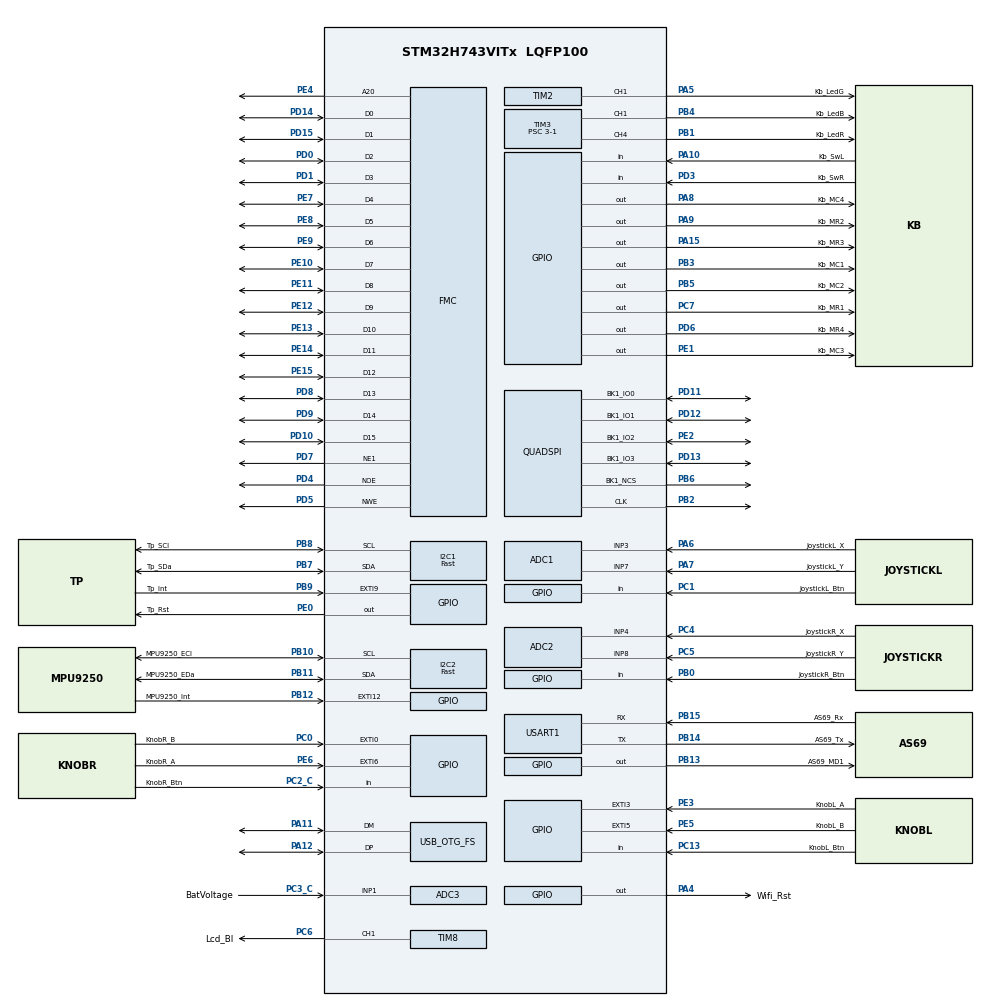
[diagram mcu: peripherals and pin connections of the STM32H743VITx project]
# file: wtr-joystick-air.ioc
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ADC1.Channel-0\#ChannelRegularConversion=ADC_CHANNEL_7
ADC1.Channel-1\#ChannelRegularConversion=ADC_CHANNEL_3
ADC1.ClockPrescaler=ADC_CLOCK_ASYNC_DIV8
ADC1.ClockPrescalerADC3=ADC_CLOCK_ASYNC_DIV8
ADC1.ContinuousConvMode=ENABLE
ADC1.ConversionDataManagement=ADC_CONVERSIONDATA_DMA_CIRCULAR
ADC1.EOCSelection=ADC_EOC_SEQ_CONV
ADC1.NbrOfConversion=2
ADC1.NbrOfConversionFlag=1
ADC1.OffsetNumber-0\#ChannelRegularConversion=ADC_OFFSET_NONE
ADC1.OffsetNumber-1\#ChannelRegularConversion=ADC_OFFSET_NONE
ADC1.OffsetSignedSaturation-0\#ChannelRegularConversion=DISABLE
ADC1.OffsetSignedSaturation-1\#ChannelRegularConversion=DISABLE
ADC1.Overrun=ADC_OVR_DATA_OVERWRITTEN
ADC1.OversamplingMode=ENABLE
ADC1.Rank-0\#ChannelRegularConversion=1
ADC1.Rank-1\#ChannelRegularConversion=2
ADC1.Ratio=128
ADC1.RightBitShift=ADC_RIGHTBITSHIFT_7
ADC1.SamplingTime-0\#ChannelRegularConversion=ADC_SAMPLETIME_16CYCLES_5
ADC1.SamplingTime-1\#ChannelRegularConversion=ADC_SAMPLETIME_16CYCLES_5
ADC1.master=1
ADC2.Channel-0\#ChannelRegularConversion=ADC_CHANNEL_8
ADC2.Channel-1\#ChannelRegularConversion=ADC_CHANNEL_4
ADC2.ClockPrescaler=ADC_CLOCK_ASYNC_DIV8
ADC2.ContinuousConvMode=ENABLE
ADC2.ConversionDataManagement=ADC_CONVERSIONDATA_DMA_CIRCULAR
ADC2.EOCSelection=ADC_EOC_SEQ_CONV
ADC2.NbrOfConversion=2
ADC2.NbrOfConversionFlag=1
ADC2.OffsetNumber-0\#ChannelRegularConversion=ADC_OFFSET_NONE
ADC2.OffsetNumber-1\#ChannelRegularConversion=ADC_OFFSET_NONE
ADC2.OffsetSignedSaturation-0\#ChannelRegularConversion=DISABLE
ADC2.OffsetSignedSaturation-1\#ChannelRegularConversion=DISABLE
ADC2.Overrun=ADC_OVR_DATA_OVERWRITTEN
ADC2.OversamplingMode=ENABLE
ADC2.Rank-0\#ChannelRegularConversion=1
ADC2.Rank-1\#ChannelRegularConversion=2
ADC2.Ratio=128
ADC2.RightBitShift=ADC_RIGHTBITSHIFT_7
ADC2.SamplingTime-0\#ChannelRegularConversion=ADC_SAMPLETIME_16CYCLES_5
ADC2.SamplingTime-1\#ChannelRegularConversion=ADC_SAMPLETIME_16CYCLES_5
ADC3.Channel-0\#ChannelRegularConversion=ADC_CHANNEL_1
ADC3.Channel-1\#ChannelRegularConversion=ADC_CHANNEL_VBAT
ADC3.Channel-2\#ChannelRegularConversion=ADC_CHANNEL_TEMPSENSOR
ADC3.Channel-3\#ChannelRegularConversion=ADC_CHANNEL_VREFINT
ADC3.ClockPrescaler=ADC_CLOCK_ASYNC_DIV8
ADC3.ClockPrescalerADC3=ADC_CLOCK_ASYNC_DIV8
ADC3.ContinuousConvMode=ENABLE
ADC3.ConversionDataManagement=ADC_CONVERSIONDATA_DMA_CIRCULAR
ADC3.EOCSelection=ADC_EOC_SEQ_CONV
ADC3.NbrOfConversion=4
ADC3.NbrOfConversionFlag=1
ADC3.OffsetNumber-0\#ChannelRegularConversion=ADC_OFFSET_NONE
ADC3.OffsetNumber-1\#ChannelRegularConversion=ADC_OFFSET_NONE
ADC3.OffsetNumber-2\#ChannelRegularConversion=ADC_OFFSET_NONE
ADC3.OffsetNumber-3\#ChannelRegularConversion=ADC_OFFSET_NONE
ADC3.OffsetSignedSaturation-0\#ChannelRegularConversion=DISABLE
ADC3.OffsetSignedSaturation-1\#ChannelRegularConversion=DISABLE
ADC3.OffsetSignedSaturation-2\#ChannelRegularConversion=DISABLE
ADC3.OffsetSignedSaturation-3\#ChannelRegularConversion=DISABLE
ADC3.Overrun=ADC_OVR_DATA_OVERWRITTEN
ADC3.OversamplingMode=ENABLE
ADC3.Rank-0\#ChannelRegularConversion=1
ADC3.Rank-1\#ChannelRegularConversion=2
ADC3.Rank-2\#ChannelRegularConversion=3
ADC3.Rank-3\#ChannelRegularConversion=4
ADC3.Ratio=1024
ADC3.RightBitShift=ADC_RIGHTBITSHIFT_10
ADC3.SamplingTime-0\#ChannelRegularConversion=ADC_SAMPLETIME_810CYCLES_5
ADC3.SamplingTime-1\#ChannelRegularConversion=ADC_SAMPLETIME_810CYCLES_5
ADC3.SamplingTime-2\#ChannelRegularConversion=ADC_SAMPLETIME_810CYCLES_5
ADC3.SamplingTime-3\#ChannelRegularConversion=ADC_SAMPLETIME_810CYCLES_5
CORTEX_M7.AccessPermission_S-Cortex_Memory_Protection_Unit_Region2_Settings_S=MPU_REGION_FULL_ACCESS
CORTEX_M7.AccessPermission_S-Cortex_Memory_Protection_Unit_Region3_Settings_S=MPU_REGION_FULL_ACCESS
CORTEX_M7.AccessPermission_S-Cortex_Memory_Protection_Unit_Region4_Settings_S=MPU_REGION_FULL_ACCESS
CORTEX_M7.AccessPermission_S-Cortex_Memory_Protection_Unit_Region5_Settings_S=MPU_REGION_FULL_ACCESS
CORTEX_M7.BaseAddress_S-Cortex_Memory_Protection_Unit_Region2_Settings_S=0x24000000
CORTEX_M7.BaseAddress_S-Cortex_Memory_Protection_Unit_Region3_Settings_S=0x30000000
CORTEX_M7.BaseAddress_S-Cortex_Memory_Protection_Unit_Region4_Settings_S=0x38000000
CORTEX_M7.BaseAddress_S-Cortex_Memory_Protection_Unit_Region5_Settings_S=0x60000000
CORTEX_M7.CPU_DCache=Enabled
CORTEX_M7.CPU_ICache=Enabled
CORTEX_M7.DisableExec_S-Cortex_Memory_Protection_Unit_Region5_Settings_S=MPU_INSTRUCTION_ACCESS_DISABLE
CORTEX_M7.Enable_S-Cortex_Memory_Protection_Unit_Region1_Settings_S=__NULL
CORTEX_M7.Enable_S-Cortex_Memory_Protection_Unit_Region2_Settings_S=MPU_REGION_ENABLE
CORTEX_M7.Enable_S-Cortex_Memory_Protection_Unit_Region3_Settings_S=MPU_REGION_ENABLE
CORTEX_M7.Enable_S-Cortex_Memory_Protection_Unit_Region4_Settings_S=MPU_REGION_ENABLE
CORTEX_M7.Enable_S-Cortex_Memory_Protection_Unit_Region5_Settings_S=MPU_REGION_ENABLE
CORTEX_M7.IsCacheable_S-Cortex_Memory_Protection_Unit_Region2_Settings_S=MPU_ACCESS_CACHEABLE
CORTEX_M7.IsCacheable_S-Cortex_Memory_Protection_Unit_Region3_Settings_S=MPU_ACCESS_CACHEABLE
CORTEX_M7.IsCacheable_S-Cortex_Memory_Protection_Unit_Region4_Settings_S=MPU_ACCESS_CACHEABLE
CORTEX_M7.IsShareable_S-Cortex_Memory_Protection_Unit_Region3_Settings_S=MPU_ACCESS_SHAREABLE
CORTEX_M7.IsShareable_S-Cortex_Memory_Protection_Unit_Region4_Settings_S=MPU_ACCESS_SHAREABLE
CORTEX_M7.IsShareable_S-Cortex_Memory_Protection_Unit_Region5_Settings_S=MPU_ACCESS_SHAREABLE
CORTEX_M7.Size_S-Cortex_Memory_Protection_Unit_Region2_Settings_S=MPU_REGION_SIZE_512KB
CORTEX_M7.Size_S-Cortex_Memory_Protection_Unit_Region3_Settings_S=MPU_REGION_SIZE_512KB
CORTEX_M7.Size_S-Cortex_Memory_Protection_Unit_Region4_Settings_S=MPU_REGION_SIZE_64KB
CORTEX_M7.Size_S-Cortex_Memory_Protection_Unit_Region5_Settings_S=MPU_REGION_SIZE_1GB
CORTEX_M7.default_mode_Activation=1
Dma.ADC1.1.Direction=DMA_PERIPH_TO_MEMORY
Dma.ADC1.1.EventEnable=DISABLE
Dma.ADC1.1.FIFOMode=DMA_FIFOMODE_ENABLE
Dma.ADC1.1.FIFOThreshold=DMA_FIFO_THRESHOLD_1QUARTERFULL
Dma.ADC1.1.Instance=DMA1_Stream1
Dma.ADC1.1.MemBurst=DMA_MBURST_SINGLE
Dma.ADC1.1.MemDataAlignment=DMA_MDATAALIGN_HALFWORD
Dma.ADC1.1.MemInc=DMA_MINC_ENABLE
Dma.ADC1.1.Mode=DMA_CIRCULAR
Dma.ADC1.1.PeriphBurst=DMA_PBURST_SINGLE
Dma.ADC1.1.PeriphDataAlignment=DMA_PDATAALIGN_HALFWORD
Dma.ADC1.1.PeriphInc=DMA_PINC_DISABLE
Dma.ADC1.1.Polarity=HAL_DMAMUX_REQ_GEN_RISING
Dma.ADC1.1.Priority=DMA_PRIORITY_LOW
Dma.ADC1.1.RequestNumber=1
Dma.ADC1.1.SignalID=NONE
Dma.ADC1.1.SyncEnable=DISABLE
Dma.ADC1.1.SyncPolarity=HAL_DMAMUX_SYNC_NO_EVENT
Dma.ADC1.1.SyncRequestNumber=1
Dma.ADC1.1.SyncSignalID=NONE
Dma.ADC2.2.Direction=DMA_PERIPH_TO_MEMORY
Dma.ADC2.2.EventEnable=DISABLE
Dma.ADC2.2.FIFOMode=DMA_FIFOMODE_ENABLE
Dma.ADC2.2.FIFOThreshold=DMA_FIFO_THRESHOLD_1QUARTERFULL
Dma.ADC2.2.Instance=DMA1_Stream2
Dma.ADC2.2.MemBurst=DMA_MBURST_SINGLE
Dma.ADC2.2.MemDataAlignment=DMA_MDATAALIGN_HALFWORD
Dma.ADC2.2.MemInc=DMA_MINC_ENABLE
Dma.ADC2.2.Mode=DMA_CIRCULAR
Dma.ADC2.2.PeriphBurst=DMA_PBURST_SINGLE
Dma.ADC2.2.PeriphDataAlignment=DMA_PDATAALIGN_HALFWORD
Dma.ADC2.2.PeriphInc=DMA_PINC_DISABLE
Dma.ADC2.2.Polarity=HAL_DMAMUX_REQ_GEN_RISING
Dma.ADC2.2.Priority=DMA_PRIORITY_LOW
Dma.ADC2.2.RequestNumber=1
Dma.ADC2.2.SignalID=NONE
Dma.ADC2.2.SyncEnable=DISABLE
Dma.ADC2.2.SyncPolarity=HAL_DMAMUX_SYNC_NO_EVENT
Dma.ADC2.2.SyncRequestNumber=1
Dma.ADC2.2.SyncSignalID=NONE
Dma.ADC3.0.Direction=DMA_PERIPH_TO_MEMORY
Dma.ADC3.0.EventEnable=DISABLE
Dma.ADC3.0.FIFOMode=DMA_FIFOMODE_ENABLE
Dma.ADC3.0.FIFOThreshold=DMA_FIFO_THRESHOLD_HALFFULL
Dma.ADC3.0.Instance=DMA1_Stream0
Dma.ADC3.0.MemBurst=DMA_MBURST_INC4
Dma.ADC3.0.MemDataAlignment=DMA_MDATAALIGN_HALFWORD
Dma.ADC3.0.MemInc=DMA_MINC_ENABLE
Dma.ADC3.0.Mode=DMA_CIRCULAR
Dma.ADC3.0.PeriphBurst=DMA_PBURST_SINGLE
Dma.ADC3.0.PeriphDataAlignment=DMA_PDATAALIGN_HALFWORD
Dma.ADC3.0.PeriphInc=DMA_PINC_DISABLE
Dma.ADC3.0.Polarity=HAL_DMAMUX_REQ_GEN_RISING
Dma.ADC3.0.Priority=DMA_PRIORITY_LOW
Dma.ADC3.0.RequestNumber=1
Dma.ADC3.0.SignalID=NONE
Dma.ADC3.0.SyncEnable=DISABLE
Dma.ADC3.0.SyncPolarity=HAL_DMAMUX_SYNC_NO_EVENT
Dma.ADC3.0.SyncRequestNumber=1
Dma.ADC3.0.SyncSignalID=NONE
Dma.Request0=ADC3
Dma.Request1=ADC1
Dma.Request2=ADC2
Dma.Request3=USART1_TX
Dma.USART1_TX.3.Direction=DMA_MEMORY_TO_PERIPH
Dma.USART1_TX.3.EventEnable=DISABLE
Dma.USART1_TX.3.FIFOMode=DMA_FIFOMODE_DISABLE
Dma.USART1_TX.3.Instance=DMA2_Stream0
Dma.USART1_TX.3.MemDataAlignment=DMA_MDATAALIGN_BYTE
Dma.USART1_TX.3.MemInc=DMA_MINC_ENABLE
Dma.USART1_TX.3.Mode=DMA_NORMAL
Dma.USART1_TX.3.PeriphDataAlignment=DMA_PDATAALIGN_BYTE
Dma.USART1_TX.3.PeriphInc=DMA_PINC_DISABLE
Dma.USART1_TX.3.Polarity=HAL_DMAMUX_REQ_GEN_RISING
Dma.USART1_TX.3.Priority=DMA_PRIORITY_HIGH
Dma.USART1_TX.3.RequestNumber=1
Dma.USART1_TX.3.SignalID=NONE
Dma.USART1_TX.3.SyncEnable=DISABLE
Dma.USART1_TX.3.SyncPolarity=HAL_DMAMUX_SYNC_NO_EVENT
Dma.USART1_TX.3.SyncRequestNumber=1
Dma.USART1_TX.3.SyncSignalID=NONE
FMC.AddressSetupTime1=0
FMC.BusTurnAroundDuration1=0
FMC.DataSetupTime1=110
FMC.ExtendedAddressSetupTime1=0
FMC.ExtendedBusTurnAroundDuration1=0
FMC.ExtendedDataSetupTime1=5
FMC.ExtendedMode1=FMC_EXTENDED_MODE_ENABLE
FREERTOS.INCLUDE_vTaskDelayUntil=1
FREERTOS.Tasks01=defaultTask,0,512,StartDefaultTask,As weak,NULL,Dynamic,NULL,NULL
FREERTOS.configENABLE_FPU=1
FREERTOS.configGENERATE_RUN_TIME_STATS=1
FREERTOS.configMAX_TASK_NAME_LEN=32
FREERTOS.configRECORD_STACK_HIGH_ADDRESS=1
FREERTOS.configTOTAL_HEAP_SIZE=131072
FREERTOS.configUSE_COUNTING_SEMAPHORES=1
FREERTOS.configUSE_NEWLIB_REENTRANT=1
FREERTOS.configUSE_POSIX_ERRNO=1
FREERTOS.configUSE_RECURSIVE_MUTEXES=1
FREERTOS.configUSE_STATS_FORMATTING_FUNCTIONS=0
FREERTOS.configUSE_TICKLESS_IDLE=2
FREERTOS.configUSE_TICK_HOOK=0
FREERTOS.configUSE_TRACE_FACILITY=0
I2C1.I2C_Speed_Mode=I2C_Fast
I2C1.Timing=0x00B03FDB
I2C2.I2C_Speed_Mode=I2C_Fast
I2C2.Timing=0x00B03FDB
Mcu.Family=STM32H7
Mcu.Name=STM32H743VITx
Mcu.Package=LQFP100
Mdma.MDMA_Channel0.Request0=SW
Mdma.MDMA_Channel0.RequestsNb=1
Mdma.MDMA_Channel0.SW.0.BlockCount=0
Mdma.MDMA_Channel0.SW.0.BlockDataLength=0
Mdma.MDMA_Channel0.SW.0.BufferTransferLength=2
Mdma.MDMA_Channel0.SW.0.CircularMode=MDMA_LINEAR_LIST
Mdma.MDMA_Channel0.SW.0.DataAlignment=MDMA_DATAALIGN_PACKENABLE
Mdma.MDMA_Channel0.SW.0.DestBlockAddressOffset=0
Mdma.MDMA_Channel0.SW.0.DestBurst=MDMA_DEST_BURST_2BEATS
Mdma.MDMA_Channel0.SW.0.DestDataSize=MDMA_DEST_DATASIZE_HALFWORD
Mdma.MDMA_Channel0.SW.0.DestinationInc=MDMA_DEST_INC_DISABLE
Mdma.MDMA_Channel0.SW.0.DstAddress=0
Mdma.MDMA_Channel0.SW.0.Endianness=MDMA_LITTLE_ENDIANNESS_PRESERVE
Mdma.MDMA_Channel0.SW.0.Instance=MDMA_Channel0
Mdma.MDMA_Channel0.SW.0.MaskAddress=0
Mdma.MDMA_Channel0.SW.0.MaskData=0
Mdma.MDMA_Channel0.SW.0.Priority=MDMA_PRIORITY_LOW
Mdma.MDMA_Channel0.SW.0.Rank=First
Mdma.MDMA_Channel0.SW.0.SourceBlockAddressOffset=0
Mdma.MDMA_Channel0.SW.0.SourceBurst=MDMA_SOURCE_BURST_2BEATS
Mdma.MDMA_Channel0.SW.0.SourceDataSize=MDMA_SRC_DATASIZE_HALFWORD
Mdma.MDMA_Channel0.SW.0.SourceInc=MDMA_SRC_INC_HALFWORD
Mdma.MDMA_Channel0.SW.0.SrcAddress=0
Mdma.MDMA_Channel0.SW.0.TransferTriggerMode=MDMA_REPEAT_BLOCK_TRANSFER
Mdma.RequestSet0=MDMA_Channel0
Mdma.RequestSetsNb=1
NVIC.EXTI0_IRQn=true\:5\:0\:true\:false\:true\:true\:true\:true\:true
NVIC.EXTI3_IRQn=true\:5\:0\:true\:false\:true\:true\:true\:true\:true
NVIC.EXTI9_5_IRQn=true\:5\:0\:true\:false\:true\:true\:true\:true\:true
NVIC.MDMA_IRQn=true\:8\:0\:true\:false\:true\:true\:false\:true\:true
NVIC.OTG_FS_IRQn=true\:11\:0\:true\:false\:true\:true\:true\:true\:true
NVIC.PriorityGroup=NVIC_PRIORITYGROUP_4
NVIC.TIM7_IRQn=true\:1\:0\:true\:false\:true\:false\:false\:true\:true
NVIC.TimeBase=TIM7_IRQn
NVIC.TimeBaseIP=TIM7
NVIC.USART1_IRQn=true\:5\:0\:false\:false\:true\:true\:true\:true\:true
PA0.GPIO_Label=Kb_UartTx
PA0.Signal=UART4_TX
PA1.GPIO_Label=Kb_UartRx
PA1.Signal=UART4_RX
PA10.GPIO_Label=Kb_SwL
PA10.GPIO_PuPd=GPIO_PULLDOWN
PA10.Signal=GPIO_Input
PA11.GPIO_Speed=GPIO_SPEED_FREQ_HIGH
PA11.Mode=Device_Only
PA11.Signal=USB_OTG_FS_DM
PA12.GPIO_Speed=GPIO_SPEED_FREQ_HIGH
PA12.Mode=Device_Only
PA12.Signal=USB_OTG_FS_DP
PA13\ (JTMS/SWDIO).Mode=Serial_Wire
PA13\ (JTMS/SWDIO).Signal=DEBUG_JTMS-SWDIO
PA14\ (JTCK/SWCLK).Mode=Serial_Wire
PA14\ (JTCK/SWCLK).Signal=DEBUG_JTCK-SWCLK
PA15\ (JTDI).GPIO_Label=Kb_MR3
PA15\ (JTDI).GPIO_ModeDefaultOutputPP=GPIO_MODE_OUTPUT_OD
PA15\ (JTDI).GPIO_PuPd=GPIO_PULLUP
PA15\ (JTDI).PinState=GPIO_PIN_SET
PA15\ (JTDI).Signal=GPIO_Output
PA2.GPIO_Label=Wifi_Tx
PA2.GPIO_Speed=GPIO_SPEED_FREQ_MEDIUM
PA2.Signal=USART2_TX
PA3.GPIO_Label=Wifi_Rx
PA3.GPIO_Speed=GPIO_SPEED_FREQ_MEDIUM
PA3.Signal=USART2_RX
PA4.GPIO_Label=Wifi_Rst
PA4.Signal=GPIO_Output
PA5.GPIO_Label=Kb_LedG
PA5.Signal=S_TIM2_CH1_ETR
PA6.GPIO_Label=JoystickL_X
PA6.Signal=ADCx_INP3
PA7.GPIO_Label=JoystickL_Y
PA7.Signal=ADCx_INP7
PA8.GPIO_Label=Kb_MC4
PA8.GPIO_ModeDefaultOutputPP=GPIO_MODE_OUTPUT_OD
PA8.GPIO_PuPd=GPIO_PULLUP
PA8.PinState=GPIO_PIN_SET
PA8.Signal=GPIO_Output
PA9.GPIO_Label=Kb_MR2
PA9.GPIO_ModeDefaultOutputPP=GPIO_MODE_OUTPUT_OD
PA9.GPIO_PuPd=GPIO_PULLUP
PA9.PinState=GPIO_PIN_SET
PA9.Signal=GPIO_Output
PB0.GPIO_Label=JoystickR_Btn
PB0.GPIO_PuPd=GPIO_PULLUP
PB0.Signal=GPIO_Input
PB1.GPIO_Label=Kb_LedR
PB1.Signal=S_TIM3_CH4
PB10.GPIO_Label=MPU9250_ECl
PB10.GPIO_Speed=GPIO_SPEED_FREQ_MEDIUM
PB10.Mode=I2C
PB10.Signal=I2C2_SCL
PB11.GPIO_Label=MPU9250_EDa
PB11.GPIO_Speed=GPIO_SPEED_FREQ_MEDIUM
PB11.Mode=I2C
PB11.Signal=I2C2_SDA
PB12.GPIO_Label=MPU9250_Int
PB12.Signal=GPXTI12
PB13.GPIO_Label=AS69_MD1
PB13.PinState=GPIO_PIN_SET
PB13.Signal=GPIO_Output
PB14.GPIO_Label=AS69_Tx
PB14.Mode=Asynchronous
PB14.Signal=USART1_TX
PB15.GPIO_Label=AS69_Rx
PB15.Mode=Asynchronous
PB15.Signal=USART1_RX
PB2.GPIO_Speed=GPIO_SPEED_FREQ_HIGH
PB2.Mode=Single Bank 1
PB2.Signal=QUADSPI_CLK
PB3\ (JTDO/TRACESWO).GPIO_Label=Kb_MC1
PB3\ (JTDO/TRACESWO).GPIO_ModeDefaultOutputPP=GPIO_MODE_OUTPUT_OD
PB3\ (JTDO/TRACESWO).GPIO_PuPd=GPIO_PULLUP
PB3\ (JTDO/TRACESWO).PinState=GPIO_PIN_SET
PB3\ (JTDO/TRACESWO).Signal=GPIO_Output
PB4\ (NJTRST).GPIO_Label=Kb_LedB
PB4\ (NJTRST).Signal=S_TIM3_CH1
PB5.GPIO_Label=Kb_MC2
PB5.GPIO_ModeDefaultOutputPP=GPIO_MODE_OUTPUT_OD
PB5.GPIO_PuPd=GPIO_PULLUP
PB5.PinState=GPIO_PIN_SET
PB5.Signal=GPIO_Output
PB6.GPIO_Speed=GPIO_SPEED_FREQ_LOW
PB6.Mode=Single Bank 1
PB6.Signal=QUADSPI_BK1_NCS
PB7.GPIO_Label=Tp_SDa
PB7.GPIO_Speed=GPIO_SPEED_FREQ_MEDIUM
PB7.Mode=I2C
PB7.Signal=I2C1_SDA
PB8.GPIO_Label=Tp_SCl
PB8.GPIO_Speed=GPIO_SPEED_FREQ_MEDIUM
PB8.Mode=I2C
PB8.Signal=I2C1_SCL
PB9.GPIO_Label=Tp_Int
PB9.Signal=GPXTI9
PC0.GPIO_Label=KnobR_B
PC0.GPIO_ModeDefaultEXTI=GPIO_MODE_IT_RISING_FALLING
PC0.GPIO_PuPd=GPIO_PULLUP
PC0.Signal=GPXTI0
PC1.GPIO_Label=JoystickL_Btn
PC1.GPIO_PuPd=GPIO_PULLUP
PC1.Signal=GPIO_Input
PC13.GPIO_Label=KnobL_Btn
PC13.GPIO_PuPd=GPIO_PULLUP
PC13.Signal=GPIO_Input
PC14-OSC32_IN\ (OSC32_IN).Mode=LSE-External-Oscillator
PC14-OSC32_IN\ (OSC32_IN).Signal=RCC_OSC32_IN
PC15-OSC32_OUT\ (OSC32_OUT).Mode=LSE-External-Oscillator
PC15-OSC32_OUT\ (OSC32_OUT).Signal=RCC_OSC32_OUT
PC2_C.GPIO_Label=KnobR_Btn
PC2_C.GPIO_PuPd=GPIO_PULLUP
PC2_C.Signal=GPIO_Input
PC3_C.GPIO_Label=BatVoltage
PC3_C.Mode=IN1-Single-Ended
PC3_C.Signal=ADC3_INP1
PC4.GPIO_Label=JoystickR_X
PC4.Signal=ADCx_INP4
PC5.GPIO_Label=JoystickR_Y
PC5.Signal=ADCx_INP8
PC6.GPIO_Label=Lcd_Bl
PC6.Signal=S_TIM8_CH1
PC7.GPIO_Label=Kb_MR1
PC7.GPIO_ModeDefaultOutputPP=GPIO_MODE_OUTPUT_OD
PC7.GPIO_PuPd=GPIO_PULLUP
PC7.PinState=GPIO_PIN_SET
PC7.Signal=GPIO_Output
PD0.Signal=FMC_D2_DA2
PD1.Signal=FMC_D3_DA3
PD10.Signal=FMC_D15_DA15
PD11.GPIO_Speed=GPIO_SPEED_FREQ_HIGH
PD11.Mode=Single Bank 1
PD11.Signal=QUADSPI_BK1_IO0
PD12.GPIO_Speed=GPIO_SPEED_FREQ_HIGH
PD12.Mode=Single Bank 1
PD12.Signal=QUADSPI_BK1_IO1
PD13.GPIO_Speed=GPIO_SPEED_FREQ_HIGH
PD13.Mode=Single Bank 1
PD13.Signal=QUADSPI_BK1_IO3
PD14.Signal=FMC_D0_DA0
PD15.Signal=FMC_D1_DA1
PD3.GPIO_Label=Kb_SwR
PD3.GPIO_PuPd=GPIO_PULLDOWN
PD3.Signal=GPIO_Input
PD4.Signal=FMC_NOE
PD5.Signal=FMC_NWE
PD6.GPIO_Label=Kb_MR4
PD6.GPIO_ModeDefaultOutputPP=GPIO_MODE_OUTPUT_OD
PD6.GPIO_PuPd=GPIO_PULLUP
PD6.PinState=GPIO_PIN_SET
PD6.Signal=GPIO_Output
PD7.Mode=NorPsramChipSelect1_1
PD7.Signal=FMC_NE1
PD8.Signal=FMC_D13_DA13
PD9.Signal=FMC_D14_DA14
PE0.GPIO_Label=Tp_Rst
PE0.Signal=GPIO_Output
PE1.GPIO_Label=Kb_MC3
PE1.GPIO_ModeDefaultOutputPP=GPIO_MODE_OUTPUT_OD
PE1.GPIO_PuPd=GPIO_PULLUP
PE1.PinState=GPIO_PIN_SET
PE1.Signal=GPIO_Output
PE10.Signal=FMC_D7_DA7
PE11.Signal=FMC_D8_DA8
PE12.Signal=FMC_D9_DA9
PE13.Signal=FMC_D10_DA10
PE14.Signal=FMC_D11_DA11
PE15.Signal=FMC_D12_DA12
PE2.GPIO_Speed=GPIO_SPEED_FREQ_HIGH
PE2.Mode=Single Bank 1
PE2.Signal=QUADSPI_BK1_IO2
PE3.GPIO_Label=KnobL_A
PE3.GPIO_ModeDefaultEXTI=GPIO_MODE_IT_RISING_FALLING
PE3.GPIO_PuPd=GPIO_PULLUP
PE3.Signal=GPXTI3
PE4.Signal=FMC_A20
PE5.GPIO_Label=KnobL_B
PE5.GPIO_ModeDefaultEXTI=GPIO_MODE_IT_RISING_FALLING
PE5.GPIO_PuPd=GPIO_PULLUP
PE5.Signal=GPXTI5
PE6.GPIO_Label=KnobR_A
PE6.GPIO_ModeDefaultEXTI=GPIO_MODE_IT_RISING_FALLING
PE6.GPIO_PuPd=GPIO_PULLUP
PE6.Signal=GPXTI6
PE7.Signal=FMC_D4_DA4
PE8.Signal=FMC_D5_DA5
PE9.Signal=FMC_D6_DA6
PH0-OSC_IN\ (PH0).Mode=HSE-External-Oscillator
PH0-OSC_IN\ (PH0).Signal=RCC_OSC_IN
PH1-OSC_OUT\ (PH1).Mode=HSE-External-Oscillator
PH1-OSC_OUT\ (PH1).Signal=RCC_OSC_OUT
ProjectManager.HeapSize=0x1000
ProjectManager.StackSize=0x1000
ProjectManager.TargetToolchain=STM32CubeIDE
RCC.ADCFreq_Value=80000000
RCC.APB1Freq_Value=120000000
RCC.APB2Freq_Value=120000000
RCC.APB3Freq_Value=120000000
RCC.APB4Freq_Value=120000000
RCC.CortexFreq_Value=480000000
RCC.D1PPRE=RCC_APB3_DIV2
RCC.D2PPRE1=RCC_APB1_DIV2
RCC.D2PPRE2=RCC_APB2_DIV2
RCC.D3PPRE=RCC_APB4_DIV2
RCC.DIVM1=5
RCC.DIVM2=5
RCC.DIVN1=192
RCC.DIVN2=80
RCC.DIVP2=5
RCC.DIVQ1=20
RCC.HCLKFreq_Value=240000000
RCC.HPRE=RCC_HCLK_DIV2
RCC.PLLSourceVirtual=RCC_PLLSOURCE_HSE
RCC.ProductRev=revV
RCC.SYSCLKFreq_VALUE=480000000
RCC.SYSCLKSource=RCC_SYSCLKSOURCE_PLLCLK
RCC.SupplySource=PWR_LDO_SUPPLY
RCC.USBFreq_Value=48000000
SH.ADCx_INP3.0=ADC1_INP3,IN3-Single-Ended
SH.ADCx_INP4.0=ADC1_INP4
SH.ADCx_INP4.1=ADC2_INP4,IN4-Single-Ended
SH.ADCx_INP7.0=ADC1_INP7,IN7-Single-Ended
SH.ADCx_INP8.0=ADC1_INP8
SH.ADCx_INP8.1=ADC2_INP8,IN8-Single-Ended
SH.FMC_A20.0=FMC_A20,A20_1
SH.FMC_D0_DA0.0=FMC_D0,16b-d1
SH.FMC_D10_DA10.0=FMC_D10,16b-d1
SH.FMC_D11_DA11.0=FMC_D11,16b-d1
SH.FMC_D12_DA12.0=FMC_D12,16b-d1
SH.FMC_D13_DA13.0=FMC_D13,16b-d1
SH.FMC_D14_DA14.0=FMC_D14,16b-d1
SH.FMC_D15_DA15.0=FMC_D15,16b-d1
SH.FMC_D1_DA1.0=FMC_D1,16b-d1
SH.FMC_D2_DA2.0=FMC_D2,16b-d1
SH.FMC_D3_DA3.0=FMC_D3,16b-d1
SH.FMC_D4_DA4.0=FMC_D4,16b-d1
SH.FMC_D5_DA5.0=FMC_D5,16b-d1
SH.FMC_D6_DA6.0=FMC_D6,16b-d1
SH.FMC_D7_DA7.0=FMC_D7,16b-d1
SH.FMC_D8_DA8.0=FMC_D8,16b-d1
SH.FMC_D9_DA9.0=FMC_D9,16b-d1
SH.FMC_NOE.0=FMC_NOE,Lcd1
SH.FMC_NWE.0=FMC_NWE,Lcd1
SH.S_TIM2_CH1_ETR.0=TIM2_CH1,PWM Generation1 CH1
SH.S_TIM3_CH1.0=TIM3_CH1,PWM Generation1 CH1
SH.S_TIM3_CH4.0=TIM3_CH4,PWM Generation4 CH4
SH.S_TIM8_CH1.0=TIM8_CH1,PWM Generation1 CH1
TIM2.AutoReloadPreload=TIM_AUTORELOAD_PRELOAD_ENABLE
TIM2.Channel-PWM\ Generation1\ CH1=TIM_CHANNEL_1
TIM2.OCPolarity_1=TIM_OCPOLARITY_LOW
TIM2.Period=65535
TIM2.Prescaler=3-1
TIM2.Pulse-PWM\ Generation1\ CH1=0
TIM3.AutoReloadPreload=TIM_AUTORELOAD_PRELOAD_ENABLE
TIM3.Channel-PWM\ Generation1\ CH1=TIM_CHANNEL_1
TIM3.Channel-PWM\ Generation4\ CH4=TIM_CHANNEL_4
TIM3.OCPolarity_1=TIM_OCPOLARITY_LOW
TIM3.OCPolarity_4=TIM_OCPOLARITY_LOW
TIM3.Period=65535
TIM3.Prescaler=3-1
TIM3.Pulse-PWM\ Generation1\ CH1=0
TIM3.Pulse-PWM\ Generation4\ CH4=0
TIM8.AutoReloadPreload=TIM_AUTORELOAD_PRELOAD_ENABLE
TIM8.Channel-PWM\ Generation1\ CH1=TIM_CHANNEL_1
TIM8.Period=1000
TIM8.Prescaler=120-1
USART1.OverrunDisableParam=ADVFEATURE_OVERRUN_DISABLE
USART1.VirtualMode-Asynchronous=VM_ASYNC
USB_DEVICE.CLASS_NAME_FS=CDC
USB_DEVICE.VirtualMode-CDC_FS=Cdc
USB_DEVICE.VirtualModeFS=Cdc_FS
USB_OTG_FS.VirtualMode=Device_Only
VP_ADC3_TempSens_Input.Mode=IN-TempSens
VP_ADC3_Vbat_Input.Mode=IN-Vbat
VP_ADC3_Vref_Input.Mode=IN-Vrefint
VP_FREERTOS_VS_CMSIS_V1.Mode=CMSIS_V1
VP_SYS_VS_tim7.Mode=TIM7
VP_TIM2_VS_ClockSourceINT.Mode=Internal
VP_TIM3_VS_ClockSourceINT.Mode=Internal
VP_TIM8_VS_ClockSourceINT.Mode=Internal
VP_USB_DEVICE_VS_USB_DEVICE_CDC_FS.Mode=CDC_FS
board=custom

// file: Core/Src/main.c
/* USER CODE BEGIN Header */
/**
  ******************************************************************************
  * @file           : main.c
  * @brief          : Main program body
  ******************************************************************************
  * @attention
  *
  * Copyright (c) 2023 STMicroelectronics.
  * All rights reserved.
  *
  * This software is licensed under terms that can be found in the LICENSE file
  * in the root directory of this software component.
  * If no LICENSE file comes with this software, it is provided AS-IS.
  *
  ******************************************************************************
  */
/* USER CODE END Header */
#include "main.h"
#include "cmsis_os.h"
#include "adc.h"
#include "dma.h"
#include "i2c.h"
#include "mdma.h"
#include "quadspi.h"
#include "tim.h"
#include "usart.h"
#include "usb_device.h"
#include "gpio.h"
#include "fmc.h"

void SystemClock_Config(void);
void PeriphCommonClock_Config(void);
static void MPU_Config(void);
void MX_FREERTOS_Init(void);

int main(void)
{

  /* MPU Configuration--------------------------------------------------------*/
  MPU_Config();

  /* Enable I-Cache---------------------------------------------------------*/
  SCB_EnableICache();

  /* Enable D-Cache---------------------------------------------------------*/
  SCB_EnableDCache();

  /* MCU Configuration--------------------------------------------------------*/

  /* Reset of all peripherals, Initializes the Flash interface and the Systick. */
  HAL_Init();

  /* Configure the system clock */
  SystemClock_Config();

/* Configure the peripherals common clocks */
  PeriphCommonClock_Config();

  /* Initialize all configured peripherals */
  MX_GPIO_Init();
  MX_MDMA_Init();
  MX_DMA_Init();
  MX_QUADSPI_Init();
  MX_ADC1_Init();
  MX_I2C1_Init();
  MX_TIM8_Init();
  MX_ADC3_Init();
  MX_I2C2_Init();
  MX_FMC_Init();
  MX_ADC2_Init();
  MX_TIM2_Init();
  MX_TIM3_Init();
  MX_USART1_UART_Init();

  /* Call init function for freertos objects (in freertos.c) */
  MX_FREERTOS_Init();

  /* Start scheduler */
  osKernelStart();

  /* We should never get here as control is now taken by the scheduler */
  /* Infinite loop */
  while (1)
  {

  }
}

void SystemClock_Config(void)
{
  RCC_OscInitTypeDef RCC_OscInitStruct = {0};
  RCC_ClkInitTypeDef RCC_ClkInitStruct = {0};

  /** Supply configuration update enable
  */
  HAL_PWREx_ConfigSupply(PWR_LDO_SUPPLY);

  /** Configure the main internal regulator output voltage
  */
  __HAL_PWR_VOLTAGESCALING_CONFIG(PWR_REGULATOR_VOLTAGE_SCALE1);

  while(!__HAL_PWR_GET_FLAG(PWR_FLAG_VOSRDY)) {}

  __HAL_RCC_SYSCFG_CLK_ENABLE();
  __HAL_PWR_VOLTAGESCALING_CONFIG(PWR_REGULATOR_VOLTAGE_SCALE0);

  while(!__HAL_PWR_GET_FLAG(PWR_FLAG_VOSRDY)) {}

  /** Macro to configure the PLL clock source
  */
  __HAL_RCC_PLL_PLLSOURCE_CONFIG(RCC_PLLSOURCE_HSE);

  /** Initializes the RCC Oscillators according to the specified parameters
  * in the RCC_OscInitTypeDef structure.
  */
  RCC_OscInitStruct.OscillatorType = RCC_OSCILLATORTYPE_HSE;
  RCC_OscInitStruct.HSEState = RCC_HSE_ON;
  RCC_OscInitStruct.PLL.PLLState = RCC_PLL_ON;
  RCC_OscInitStruct.PLL.PLLSource = RCC_PLLSOURCE_HSE;
  RCC_OscInitStruct.PLL.PLLM = 5;
  RCC_OscInitStruct.PLL.PLLN = 192;
  RCC_OscInitStruct.PLL.PLLP = 2;
  RCC_OscInitStruct.PLL.PLLQ = 20;
  RCC_OscInitStruct.PLL.PLLR = 2;
  RCC_OscInitStruct.PLL.PLLRGE = RCC_PLL1VCIRANGE_2;
  RCC_OscInitStruct.PLL.PLLVCOSEL = RCC_PLL1VCOWIDE;
  RCC_OscInitStruct.PLL.PLLFRACN = 0;
  if (HAL_RCC_OscConfig(&RCC_OscInitStruct) != HAL_OK)
  {
    Error_Handler();
  }

  /** Initializes the CPU, AHB and APB buses clocks
  */
  RCC_ClkInitStruct.ClockType = RCC_CLOCKTYPE_HCLK|RCC_CLOCKTYPE_SYSCLK
                              |RCC_CLOCKTYPE_PCLK1|RCC_CLOCKTYPE_PCLK2
                              |RCC_CLOCKTYPE_D3PCLK1|RCC_CLOCKTYPE_D1PCLK1;
  RCC_ClkInitStruct.SYSCLKSource = RCC_SYSCLKSOURCE_PLLCLK;
  RCC_ClkInitStruct.SYSCLKDivider = RCC_SYSCLK_DIV1;
  RCC_ClkInitStruct.AHBCLKDivider = RCC_HCLK_DIV2;
  RCC_ClkInitStruct.APB3CLKDivider = RCC_APB3_DIV2;
  RCC_ClkInitStruct.APB1CLKDivider = RCC_APB1_DIV2;
  RCC_ClkInitStruct.APB2CLKDivider = RCC_APB2_DIV2;
  RCC_ClkInitStruct.APB4CLKDivider = RCC_APB4_DIV2;

  if (HAL_RCC_ClockConfig(&RCC_ClkInitStruct, FLASH_LATENCY_4) != HAL_OK)
  {
    Error_Handler();
  }
}

void PeriphCommonClock_Config(void)
{
  RCC_PeriphCLKInitTypeDef PeriphClkInitStruct = {0};

  /** Initializes the peripherals clock
  */
  PeriphClkInitStruct.PeriphClockSelection = RCC_PERIPHCLK_ADC;
  PeriphClkInitStruct.PLL2.PLL2M = 5;
  PeriphClkInitStruct.PLL2.PLL2N = 80;
  PeriphClkInitStruct.PLL2.PLL2P = 5;
  PeriphClkInitStruct.PLL2.PLL2Q = 2;
  PeriphClkInitStruct.PLL2.PLL2R = 2;
  PeriphClkInitStruct.PLL2.PLL2RGE = RCC_PLL2VCIRANGE_2;
  PeriphClkInitStruct.PLL2.PLL2VCOSEL = RCC_PLL2VCOWIDE;
  PeriphClkInitStruct.PLL2.PLL2FRACN = 0;
  PeriphClkInitStruct.AdcClockSelection = RCC_ADCCLKSOURCE_PLL2;
  if (HAL_RCCEx_PeriphCLKConfig(&PeriphClkInitStruct) != HAL_OK)
  {
    Error_Handler();
  }
}

/* MPU Configuration */

void MPU_Config(void)
{
  MPU_Region_InitTypeDef MPU_InitStruct = {0};

  /* Disables the MPU */
  HAL_MPU_Disable();

  /** Initializes and configures the Region and the memory to be protected
  */
  MPU_InitStruct.Enable = MPU_REGION_ENABLE;
  MPU_InitStruct.Number = MPU_REGION_NUMBER0;
  MPU_InitStruct.BaseAddress = 0x0;
  MPU_InitStruct.Size = MPU_REGION_SIZE_4GB;
  MPU_InitStruct.SubRegionDisable = 0x87;
  MPU_InitStruct.TypeExtField = MPU_TEX_LEVEL0;
  MPU_InitStruct.AccessPermission = MPU_REGION_NO_ACCESS;
  MPU_InitStruct.DisableExec = MPU_INSTRUCTION_ACCESS_DISABLE;
  MPU_InitStruct.IsShareable = MPU_ACCESS_SHAREABLE;
  MPU_InitStruct.IsCacheable = MPU_ACCESS_NOT_CACHEABLE;
  MPU_InitStruct.IsBufferable = MPU_ACCESS_NOT_BUFFERABLE;

  HAL_MPU_ConfigRegion(&MPU_InitStruct);

  /** Initializes and configures the Region and the memory to be protected
  */
  MPU_InitStruct.Number = MPU_REGION_NUMBER2;
  MPU_InitStruct.BaseAddress = 0x24000000;
  MPU_InitStruct.Size = MPU_REGION_SIZE_512KB;
  MPU_InitStruct.SubRegionDisable = 0x0;
  MPU_InitStruct.AccessPermission = MPU_REGION_FULL_ACCESS;
  MPU_InitStruct.DisableExec = MPU_INSTRUCTION_ACCESS_ENABLE;
  MPU_InitStruct.IsShareable = MPU_ACCESS_NOT_SHAREABLE;
  MPU_InitStruct.IsCacheable = MPU_ACCESS_CACHEABLE;

  HAL_MPU_ConfigRegion(&MPU_InitStruct);

  /** Initializes and configures the Region and the memory to be protected
  */
  MPU_InitStruct.Number = MPU_REGION_NUMBER3;
  MPU_InitStruct.BaseAddress = 0x30000000;
  MPU_InitStruct.IsShareable = MPU_ACCESS_SHAREABLE;

  HAL_MPU_ConfigRegion(&MPU_InitStruct);

  /** Initializes and configures the Region and the memory to be protected
  */
  MPU_InitStruct.Number = MPU_REGION_NUMBER4;
  MPU_InitStruct.BaseAddress = 0x38000000;
  MPU_InitStruct.Size = MPU_REGION_SIZE_64KB;

  HAL_MPU_ConfigRegion(&MPU_InitStruct);

  /** Initializes and configures the Region and the memory to be protected
  */
  MPU_InitStruct.Number = MPU_REGION_NUMBER5;
  MPU_InitStruct.BaseAddress = 0x60000000;
  MPU_InitStruct.Size = MPU_REGION_SIZE_1GB;
  MPU_InitStruct.DisableExec = MPU_INSTRUCTION_ACCESS_DISABLE;
  MPU_InitStruct.IsCacheable = MPU_ACCESS_NOT_CACHEABLE;

  HAL_MPU_ConfigRegion(&MPU_InitStruct);
  /* Enables the MPU */
  HAL_MPU_Enable(MPU_PRIVILEGED_DEFAULT);

}

void HAL_TIM_PeriodElapsedCallback(TIM_HandleTypeDef *htim)
{
  if (htim->Instance == TIM7) {
    HAL_IncTick();
  }
}

void Error_Handler(void)
{
  __disable_irq();
  while (1)
  {
  }
}

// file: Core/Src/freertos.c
/* USER CODE BEGIN Header */
/**
  ******************************************************************************
  * File Name          : freertos.c
  * Description        : Code for freertos applications
  ******************************************************************************
  * @attention
  *
  * Copyright (c) 2023 STMicroelectronics.
  * All rights reserved.
  *
  * This software is licensed under terms that can be found in the LICENSE file
  * in the root directory of this software component.
  * If no LICENSE file comes with this software, it is provided AS-IS.
  *
  ******************************************************************************
  */
/* USER CODE END Header */

#include "FreeRTOS.h"
#include "task.h"
#include "main.h"
#include "cmsis_os.h"

osThreadId defaultTaskHandle;

void StartDefaultTask(void const * argument);

extern void MX_USB_DEVICE_Init(void);
void MX_FREERTOS_Init(void); /* (MISRA C 2004 rule 8.1) */

/* GetIdleTaskMemory prototype (linked to static allocation support) */
void vApplicationGetIdleTaskMemory( StaticTask_t **ppxIdleTaskTCBBuffer, StackType_t **ppxIdleTaskStackBuffer, uint32_t *pulIdleTaskStackSize );

/* Hook prototypes */
void configureTimerForRunTimeStats(void);
unsigned long getRunTimeCounterValue(void);

/* USER CODE BEGIN 1 */
/* Functions needed when configGENERATE_RUN_TIME_STATS is on */
__weak void configureTimerForRunTimeStats(void)
{

}

__weak unsigned long getRunTimeCounterValue(void)
{
return 0;
}
/* USER CODE END 1 */

/* USER CODE BEGIN VPORT_SUPPORT_TICKS_AND_SLEEP */
__weak void vPortSuppressTicksAndSleep( TickType_t xExpectedIdleTime )
{
  // Generated when configUSE_TICKLESS_IDLE == 2.
  // Function called in tasks.c (in portTASK_FUNCTION).
  // TO BE COMPLETED or TO BE REPLACED by a user one, overriding that weak one.
}
/* USER CODE END VPORT_SUPPORT_TICKS_AND_SLEEP */

/* USER CODE BEGIN GET_IDLE_TASK_MEMORY */
static StaticTask_t xIdleTaskTCBBuffer;
static StackType_t xIdleStack[configMINIMAL_STACK_SIZE];

void vApplicationGetIdleTaskMemory( StaticTask_t **ppxIdleTaskTCBBuffer, StackType_t **ppxIdleTaskStackBuffer, uint32_t *pulIdleTaskStackSize )
{
  *ppxIdleTaskTCBBuffer = &xIdleTaskTCBBuffer;
  *ppxIdleTaskStackBuffer = &xIdleStack[0];
  *pulIdleTaskStackSize = configMINIMAL_STACK_SIZE;
  /* place for user code */
}
/* USER CODE END GET_IDLE_TASK_MEMORY */

void MX_FREERTOS_Init(void) {

  /* Create the thread(s) */
  /* definition and creation of defaultTask */
  osThreadDef(defaultTask, StartDefaultTask, osPriorityNormal, 0, 512);
  defaultTaskHandle = osThreadCreate(osThread(defaultTask), NULL);

}

__weak void StartDefaultTask(void const * argument)
{
  /* init code for USB_DEVICE */
  MX_USB_DEVICE_Init();
  for(;;)
  {
    osDelay(1);
  }
}
